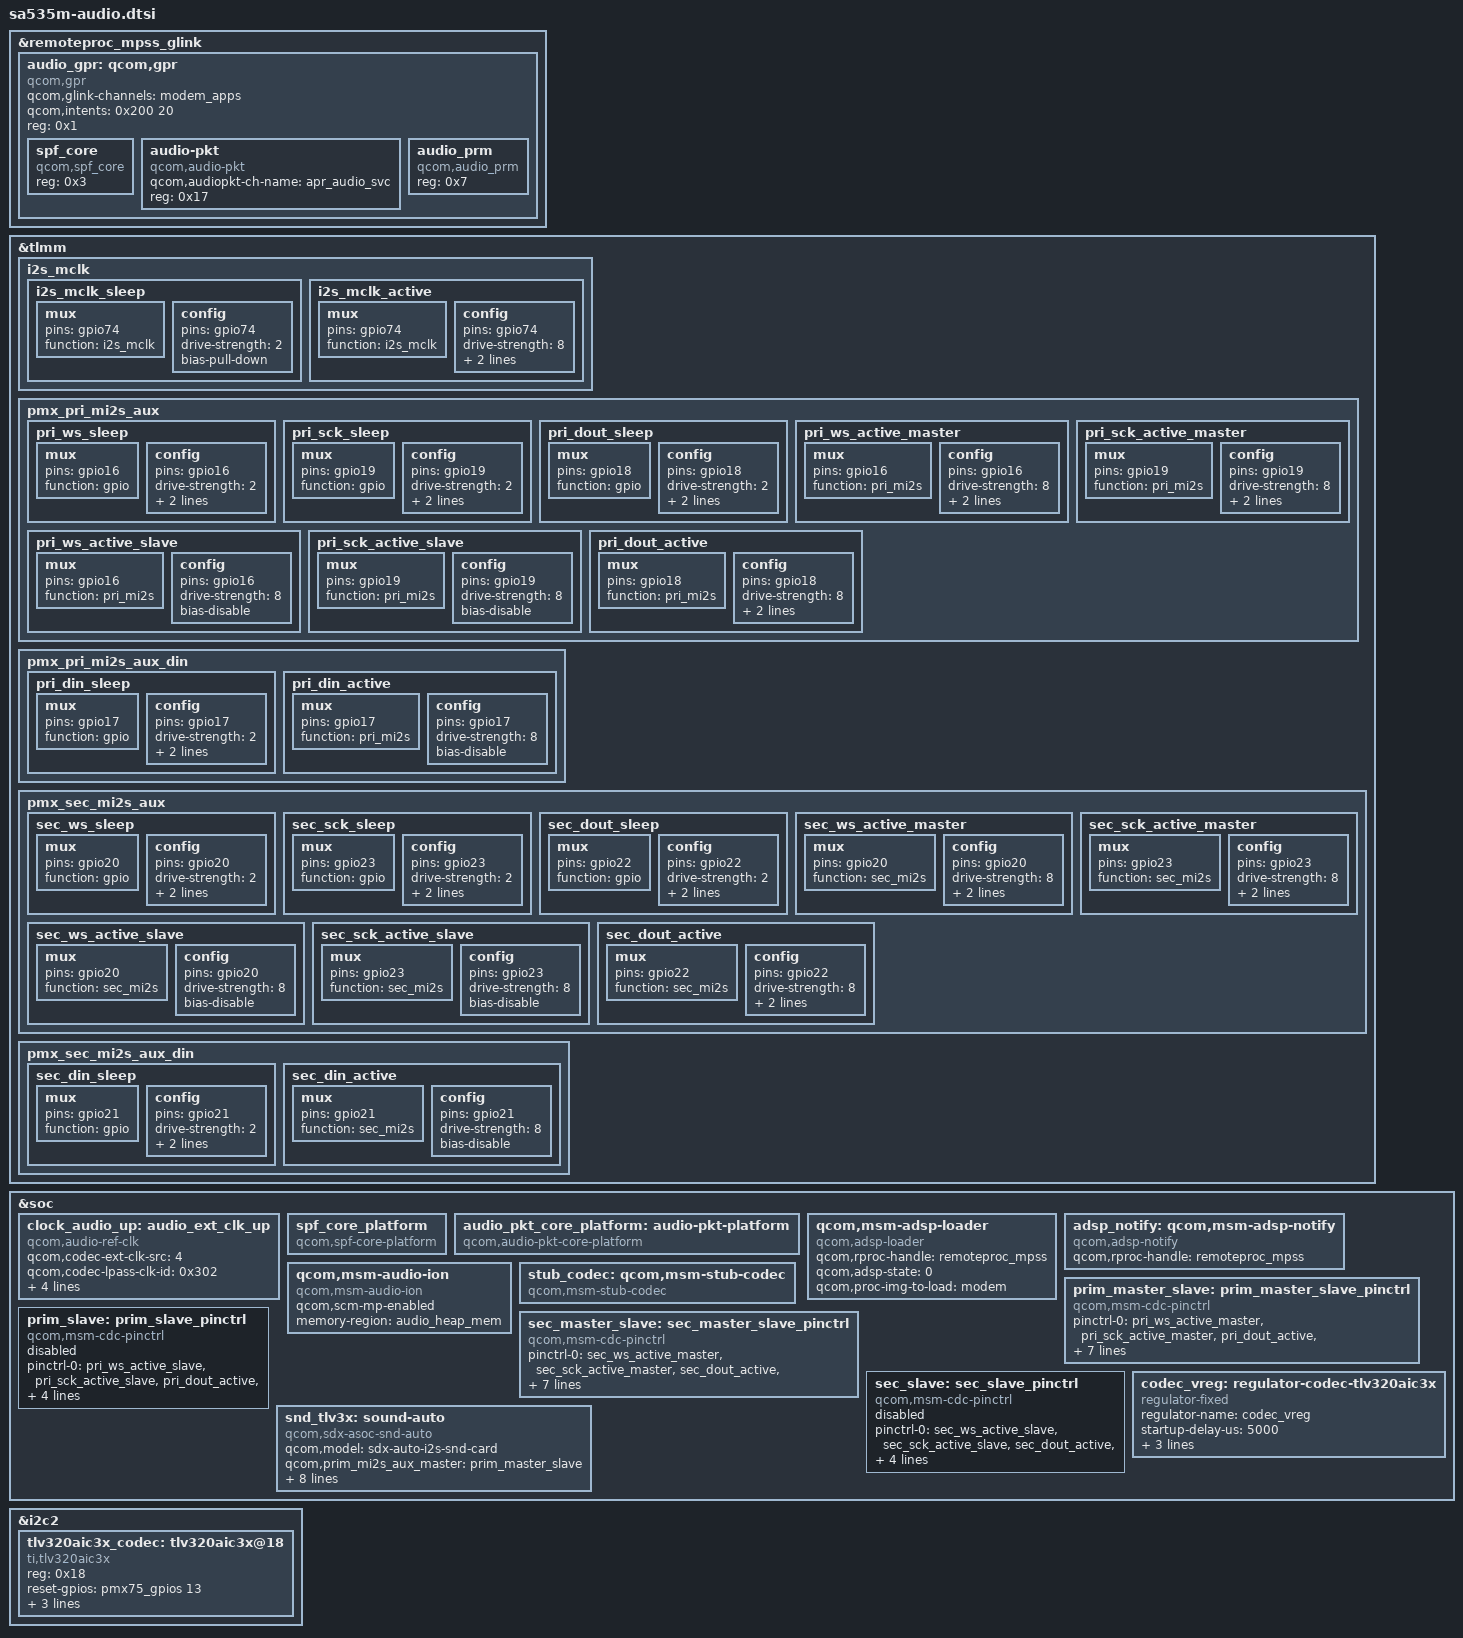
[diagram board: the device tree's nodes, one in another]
/*
* Copyright (c) Qualcomm Technologies, Inc. and/or its subsidiaries.
* SPDX-License-Identifier: BSD-3-Clause
*/

#include <dt-bindings/gpio/gpio.h>

&remoteproc_mpss_glink {
	audio_gpr: qcom,gpr {
		compatible = "qcom,gpr";
		qcom,glink-channels = "modem_apps";
		qcom,intents = <0x200 20>;
		reg = <0x1>;

		spf_core {
			compatible = "qcom,spf_core";
			reg = <0x3>;
		};

		audio-pkt {
			compatible = "qcom,audio-pkt";
			qcom,audiopkt-ch-name = "apr_audio_svc";
			reg = <0x17>;
		};

		audio_prm {
			compatible = "qcom,audio_prm";
			reg = <0x7>;
		};
	};
};

&tlmm {

	i2s_mclk {
		i2s_mclk_sleep: i2s_mclk_sleep {
			mux {
				pins = "gpio74";
				function = "i2s_mclk";
			};

			config {
				pins = "gpio74";
				drive-strength = <2>;	/* 2 mA */
				bias-pull-down;		/* PULL DOWN */
			};
		};

		i2s_mclk_active: i2s_mclk_active {
			mux {
				pins = "gpio74";
				function = "i2s_mclk";
			};

			config {
				pins = "gpio74";
				drive-strength = <8>;	/* 8 mA */
				bias-disable;		/* NO PULL*/
				output-high;
			};
		};
	};

	pmx_pri_mi2s_aux {
		pri_ws_sleep: pri_ws_sleep {
			mux {
				pins = "gpio16";
				function = "gpio";
			};

			config {
				pins = "gpio16";
				drive-strength = <2>;	/* 2 mA */
				bias-pull-down;		/* PULL DOWN */
				input-enable;
			};
		};

		pri_sck_sleep: pri_sck_sleep {
			mux {
				pins = "gpio19";
				function = "gpio";
			};

			config {
				pins = "gpio19";
				drive-strength = <2>;	/* 2 mA */
				bias-pull-down;		/* PULL DOWN */
				input-enable;
			};
		};

		pri_dout_sleep: pri_dout_sleep {
			mux {
				pins = "gpio18";
				function = "gpio";
			};

			config {
				pins = "gpio18";
				drive-strength = <2>;	/* 2 mA */
				bias-pull-down;		/* PULL DOWN */
				input-enable;
			};
		};

		pri_ws_active_master: pri_ws_active_master {
			mux {
				pins = "gpio16";
				function = "pri_mi2s";
			};

			config {
				pins = "gpio16";
				drive-strength = <8>;	/* 8 mA */
				bias-disable;		/* NO PULL*/
				output-high;
			};
		};

		pri_sck_active_master: pri_sck_active_master {
			mux {
				pins = "gpio19";
				function = "pri_mi2s";
			};

			config {
				pins = "gpio19";
				drive-strength = <8>;	/* 8 mA */
				bias-disable;		/* NO PULL*/
				output-high;
			};
		};

		pri_ws_active_slave: pri_ws_active_slave {
			mux {
				pins = "gpio16";
				function = "pri_mi2s";
			};

			config {
				pins = "gpio16";
				drive-strength = <8>;	/* 8 mA */
				bias-disable;		/* NO PULL*/
			};
		};

		pri_sck_active_slave: pri_sck_active_slave {
			mux {
				pins = "gpio19";
				function = "pri_mi2s";
			};

			config {
				pins = "gpio19";
				drive-strength = <8>;	/* 8 mA */
				bias-disable;		/* NO PULL*/
			};
		};

		pri_dout_active: pri_dout_active {
			mux {
				pins = "gpio18";
				function = "pri_mi2s";
			};

			config {
				pins = "gpio18";
				drive-strength = <8>;	/* 8 mA */
				bias-disable;		/* NO PULL*/
				output-high;
			};
		};
	};

	pmx_pri_mi2s_aux_din {
		pri_din_sleep: pri_din_sleep {
			mux {
				pins = "gpio17";
				function = "gpio";
			};

			config {
				pins = "gpio17";
				drive-strength = <2>;	/* 2 mA */
				bias-pull-down;		/* PULL DOWN */
				input-enable;
			};
		};

		pri_din_active: pri_din_active {
			mux {
				pins = "gpio17";
				function = "pri_mi2s";
			};

			config {
				pins = "gpio17";
				drive-strength = <8>;	/* 8 mA */
				bias-disable;		/* NO PULL */
			};
		};
	};

	pmx_sec_mi2s_aux {
		sec_ws_sleep: sec_ws_sleep {
			mux {
				pins = "gpio20";
				function = "gpio";
			};

			config {
				pins = "gpio20";
				drive-strength = <2>;	/* 2 mA */
				bias-pull-down;		/* PULL DOWN */
				input-enable;
			};
		};

		sec_sck_sleep: sec_sck_sleep {
			mux {
				pins = "gpio23";
				function = "gpio";
			};

			config {
				pins = "gpio23";
				drive-strength = <2>;	/* 2 mA */
				bias-pull-down;		/* PULL DOWN */
				input-enable;
			};
		};

		sec_dout_sleep: sec_dout_sleep {
			mux {
				pins = "gpio22";
				function = "gpio";
			};

			config {
				pins = "gpio22";
				drive-strength = <2>;	/* 2 mA */
				bias-pull-down;		/* PULL DOWN */
				input-enable;
			};
		};

		sec_ws_active_master: sec_ws_active_master {
			mux {
				pins = "gpio20";
				function = "sec_mi2s";
			};

			config {
				pins = "gpio20";
				drive-strength = <8>;	/* 8 mA */
				bias-disable;		/* NO PULL*/
				output-high;
			};
		};

		sec_sck_active_master: sec_sck_active_master {
			mux {
				pins = "gpio23";
				function = "sec_mi2s";
			};

			config {
				pins = "gpio23";
				drive-strength = <8>;	/* 8 mA */
				bias-disable;		/* NO PULL*/
				output-high;
			};
		};

		sec_ws_active_slave: sec_ws_active_slave {
			mux {
				pins = "gpio20";
				function = "sec_mi2s";
			};

			config {
				pins = "gpio20";
				drive-strength = <8>;	/* 8 mA */
				bias-disable;		/* NO PULL*/
			};
		};

		sec_sck_active_slave: sec_sck_active_slave {
			mux {
				pins = "gpio23";
				function = "sec_mi2s";
			};

			config {
				pins = "gpio23";
				drive-strength = <8>;	/* 8 mA */
				bias-disable;		/* NO PULL*/
			};
		};

		sec_dout_active: sec_dout_active {
			mux {
				pins = "gpio22";
				function = "sec_mi2s";
			};

			config {
				pins = "gpio22";
				drive-strength = <8>;	/* 8 mA */
				bias-disable;		/* NO PULL*/
				output-high;
			};
		};
	};

	pmx_sec_mi2s_aux_din {
		sec_din_sleep: sec_din_sleep {
			mux {
				pins = "gpio21";
				function = "gpio";
			};

			config {
				pins = "gpio21";
				drive-strength = <2>;	/* 2 mA */
				bias-disable;		/* NO PULL */
				input-enable;
			};
		};

		sec_din_active: sec_din_active {
			mux {
				pins = "gpio21";
				function = "sec_mi2s";
			};

			config {
				pins = "gpio21";
				drive-strength = <8>;	/* 8 mA */
				bias-disable;		/* NO PULL */
			};
		};
	};
};

&soc {
	clock_audio_up: audio_ext_clk_up {
		compatible = "qcom,audio-ref-clk";
		qcom,codec-ext-clk-src = <4>;
		qcom,codec-lpass-clk-id = <0x302>;
		qcom,codec-lpass-ext-clk-freq = <9600000>;
		qcom,use-pinctrl = <1>;
		pinctrl-names = "sleep", "active";
		pinctrl-0 = <&i2s_mclk_sleep>;
		pinctrl-1 = <&i2s_mclk_active>;
		#clock-cells = <1>;
	};

	spf_core_platform: spf_core_platform {
		compatible = "qcom,spf-core-platform";
	};

	audio_pkt_core_platform: audio-pkt-platform {
		compatible = "qcom,audio-pkt-core-platform";
	};

	qcom,msm-adsp-loader {
		compatible = "qcom,adsp-loader";
		qcom,rproc-handle = <&remoteproc_mpss>;
		qcom,adsp-state = <0>;
		qcom,proc-img-to-load = "modem";
	};

	adsp_notify: qcom,msm-adsp-notify {
		status = "ok";
		compatible = "qcom,adsp-notify";
		qcom,rproc-handle = <&remoteproc_mpss>;
	};

	qcom,msm-audio-ion {
		compatible = "qcom,msm-audio-ion";
		qcom,scm-mp-enabled;
		memory-region = <&audio_heap_mem>;
	};

	stub_codec: qcom,msm-stub-codec {
		compatible = "qcom,msm-stub-codec";
	};

	prim_master_slave: prim_master_slave_pinctrl {
		compatible = "qcom,msm-cdc-pinctrl";
		pinctrl-names = "aud_active", "aud_sleep", "aud_alt_active";
		pinctrl-0 = <&pri_ws_active_master
				&pri_sck_active_master
				&pri_dout_active
				&pri_din_active>;
		pinctrl-1 = <&pri_ws_sleep
				&pri_sck_sleep
				&pri_dout_sleep
				&pri_din_sleep>;
		pinctrl-2 = <&pri_ws_active_slave
				&pri_sck_active_slave
				&pri_dout_active
				&pri_din_active>;
		qcom,mi2s-auxpcm-cdc-gpios;
	};

	prim_slave: prim_slave_pinctrl {
		status = "disabled";
		compatible = "qcom,msm-cdc-pinctrl";
		pinctrl-names = "aud_active", "aud_sleep";
		pinctrl-0 = <&pri_ws_active_slave
				&pri_sck_active_slave
				&pri_dout_active
				&pri_din_active>;
		pinctrl-1 = <&pri_ws_sleep
				&pri_sck_sleep
				&pri_dout_sleep
				&pri_din_sleep>;
		qcom,mi2s-auxpcm-cdc-gpios;
	};

	sec_master_slave: sec_master_slave_pinctrl {
		compatible = "qcom,msm-cdc-pinctrl";
		pinctrl-names = "aud_active", "aud_sleep", "aud_alt_active";
		pinctrl-0 = <&sec_ws_active_master
				&sec_sck_active_master
				&sec_dout_active
				&sec_din_active>;
		pinctrl-1 = <&sec_ws_sleep
				&sec_sck_sleep
				&sec_dout_sleep
				&sec_din_sleep>;
		pinctrl-2 = <&sec_ws_active_slave
				&sec_sck_active_slave
				&sec_dout_active
				&sec_din_active>;
		qcom,mi2s-auxpcm-cdc-gpios;
	};

	sec_slave: sec_slave_pinctrl {
		status = "disabled";
		compatible = "qcom,msm-cdc-pinctrl";
		pinctrl-names = "aud_active", "aud_sleep";
		pinctrl-0 = <&sec_ws_active_slave
				&sec_sck_active_slave
				&sec_dout_active
				&sec_din_active>;
		pinctrl-1 = <&sec_ws_sleep
				&sec_sck_sleep
				&sec_dout_sleep
				&sec_din_sleep>;
		qcom,mi2s-auxpcm-cdc-gpios;
	};
};

&soc {
	codec_vreg: regulator-codec-tlv320aic3x {
		compatible = "regulator-fixed";
		regulator-name = "codec_vreg";
		startup-delay-us = <5000>;
		gpio = <&pmx75_gpios 5 GPIO_ACTIVE_HIGH>;
		enable-active-high;
		regulator-always-on;
	};
};

&i2c2 {
	status = "ok";
	tlv320aic3x_codec: tlv320aic3x@18 {
		compatible = "ti,tlv320aic3x";
		reg = <0x18>;
		reset-gpios = <&pmx75_gpios 13 GPIO_ACTIVE_HIGH>;
		AVDD-supply = <&codec_vreg>;
		IOVDD-supply = <&codec_vreg>;
		ai3x-ocmv = <1>;
	};
};

&soc {

	snd_tlv3x: sound-auto {
		compatible = "qcom,sdx-asoc-snd-auto";
		qcom,model = "sdx-auto-i2s-snd-card";
		qcom,prim_mi2s_aux_master = <&prim_master_slave>;
		qcom,prim_mi2s_aux_slave = <&prim_slave>;
		qcom,sec_mi2s_aux_master = <&sec_master_slave>;
		qcom,sec_mi2s_aux_slave = <&sec_slave>;

		pinctrl-names = "default";
		pinctrl-0 = <&i2s_mclk_active>;
		asoc-codec = <&tlv320aic3x_codec>, <&stub_codec>;
		asoc-codec-names = "tlv320aic3x", "msm-stub-codec.1";
		qcom,msm_audio_ssr_devs = <&audio_gpr>;
	};
};
